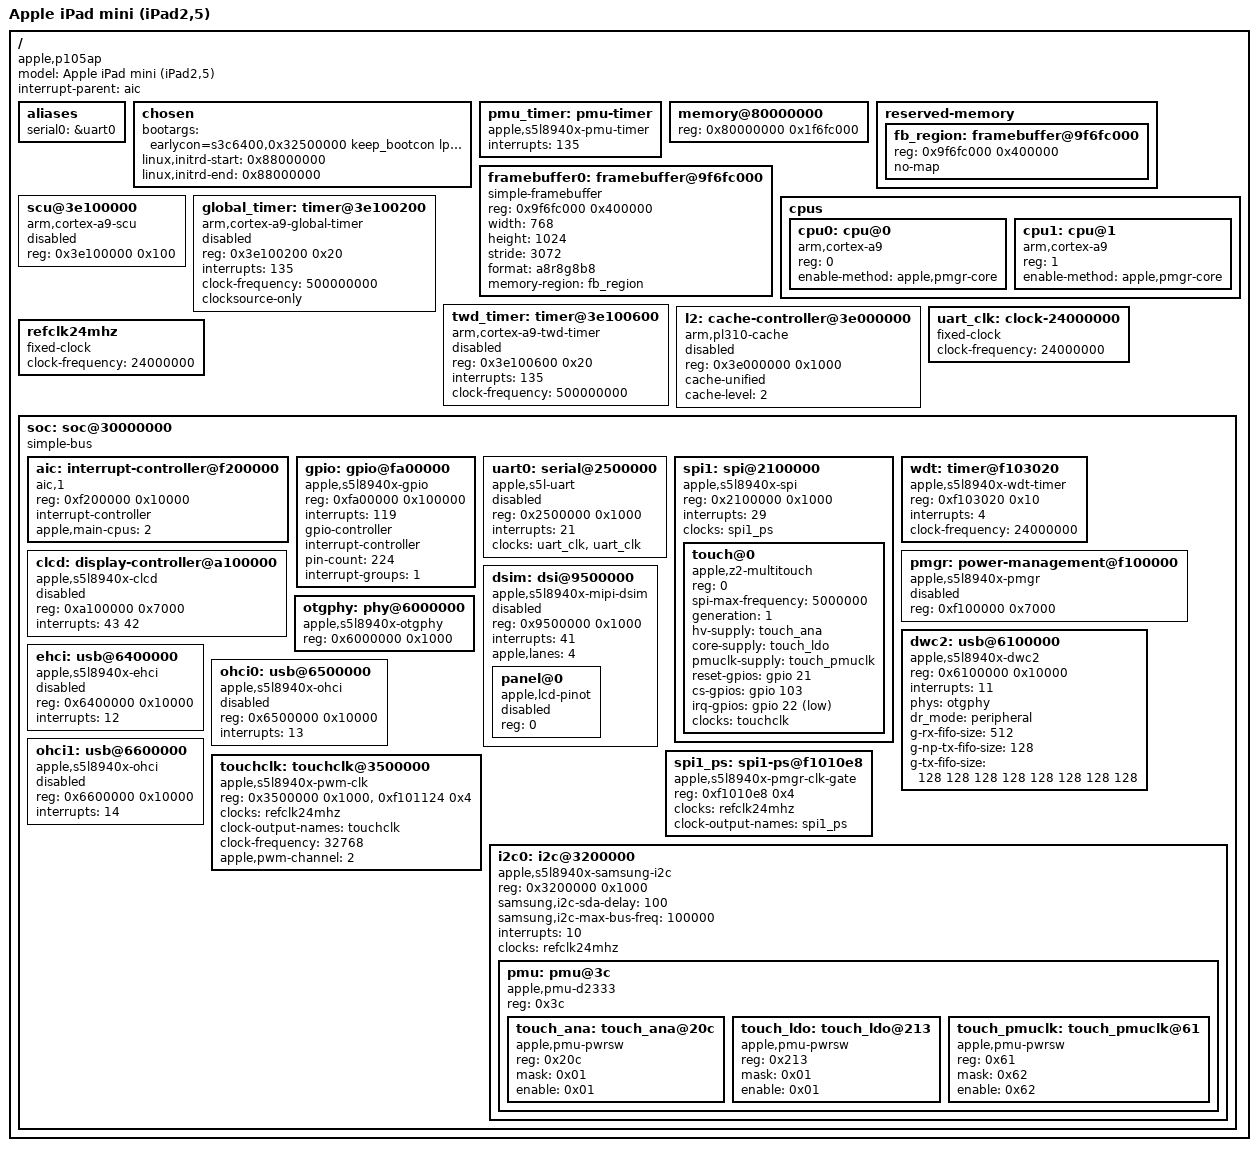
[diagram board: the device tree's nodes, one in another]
// SPDX-License-Identifier: GPL-2.0 OR MIT
/*
 * Apple iPad mini, 1st generation -- iPad2,5 / P105AP / S5L8942X (Apple A5).
 *
 * GENERATED FILE.  Do not edit by hand; edit scripts/gen_p105ap_dts.py and
 * re-run "make dts".  Every reg/interrupt below was read out of the iBoot
 * Apple Device Tree in src/adt-p105ap.bin, not transcribed from a datasheet.
 *
 * Scope: the minimum needed to bring Alpine + LXDE up on the glass, per
 * alpine-lxde-ramdisk-buildplan.md -- UART console, interrupt controller,
 * timer, simple-framebuffer, and an SPI transport for the touch controller.
 * NAND, GPU, ISP, audio, cameras and the sensor I2C buses are deliberately
 * absent; see DECISIONS.md.
 *
 * Address model
 * -------------
 * The ADT's "arm-io" node is a bus whose children use bus-local addresses:
 *   ranges = <0x0 0x30000000 0x10000000>
 * We keep that structure as /soc so unit addresses match the ADT one-for-one
 * and cross-checking against a fresh dump stays trivial.  usb-complex is a
 * second, nested bus; its children are flattened into /soc here because
 * nothing in Linux needs the extra level.
 *
 * Boot protocol (32-bit ARM):
 *   r0 = 0, r1 = ~0 (DT-only boot, no machine ID), r2 = <dtb physical address>
 */

/dts-v1/;

/ {
	compatible = "apple,p105ap", "apple,s5l8942x", "apple,s5l8940x", "apple,arm";
	model = "Apple iPad mini (iPad2,5)";
	#address-cells = <1>;
	#size-cells = <1>;
	interrupt-parent = <&aic>;

	aliases {
		serial0 = &uart0;
	};

	chosen {
		/*
		 * earlycon uses the Samsung s3c6400 driver: the S5L UART is a
		 * Samsung derivative with an identical register file (ULCON 0x00,
		 * UCON 0x04, UFCON 0x08, UTRSTAT 0x10, UTXH 0x20, URXH 0x24,
		 * UBRDIV 0x28).  See DECISIONS.md #3.
		 *
		 * No baud rate is given to earlycon on purpose: that tells it to
		 * keep whatever divisor iBoot already programmed, which avoids
		 * needing a clock rate we do not know.
		 *
		 * keep_bootcon matters here.  The full ttySAC0 port needs a clock
		 * provider; without keep_bootcon the kernel would drop earlycon
		 * if UART probe/baud fails.
		 *
		 * console=tty0 only.  Do NOT set stdout-path to serial0 — OF
		 * would still prefer ttySAC0 on probe (legacy console enabled)
		 * and /dev/console open fails for init.  UART still probes for
		 * /dev/ttySAC0; earlycon+keep_bootcon covers pre-fbcon printk.
		 */
		/*
		 * g_cdc.dev_addr / g_cdc.host_addr pin the two ends of the CDC
		 * ECM link.  Without them u_ether picks a fresh random MAC on
		 * every boot, and because macOS keys its interface names off the
		 * MAC, the gadget lands on a NEW enN each time -- en10, en11,
		 * en12 -- so the host-side ifconfig has to be redone every boot.
		 * Observed directly: 6e:f1:1c:27:f4:65 on one boot and
		 * da:5b:e0:9b:ef:1d on the next.
		 *
		 * Both are locally-administered unicast (low nibble of the first
		 * octet is 2), so they cannot collide with a real vendor OUI.
		 *   ...:01 = host side (the Mac's enN)
		 *   ...:02 = device side (usb0 here)
		 */
		bootargs = "earlycon=s3c6400,0x32500000 keep_bootcon lpj=5000000 root=/dev/ram0 rw rootwait panic=10 loglevel=8 ignore_loglevel g_cdc.host_addr=02:10:5a:05:00:01 g_cdc.dev_addr=02:10:5a:05:00:02";

		/*
		 * Placeholders.  The loader MUST overwrite both before jumping;
		 * scripts/fdt_fixup.py and the pongoOS module in pongo/ do this.
		 * Leaving them equal means "no initrd", which is a safe default.
		 */
		linux,initrd-start = <0x88000000>;
		linux,initrd-end   = <0x88000000>;
	};

	/*
	 * S5L894x maps DRAM at 0x80000000; iPad2,5 populates 512 MiB.
	 * The static ADT /memory node is zeroed (iBoot fills it at runtime),
	 * so this is a fixed constant rather than an extracted value.
	 */
	/*
	 * System tick from the Cortex-A9 PMU overflow interrupt.  No reg: the
	 * whole thing is CP15.
	 *
	 * hwirq 135 comes out of the ADT: cpu0 interrupts = <192, 135, 193> and
	 * cpu1 = <194, 139, 195>, with function-ipi_dispatch pointing at 192 and
	 * ipi_dispatch_other at 193 -- so the outer two are IPIs and the middle
	 * one is the per-CPU interrupt.  aic target-destinations = <135 cpu0,
	 * 139 cpu1> pins each to its own core.  On an A9 with no architected
	 * timer, that per-CPU line is nPMUIRQ.
	 */
	pmu_timer: pmu-timer {
		compatible = "apple,s5l8940x-pmu-timer";
		interrupts = <135>;
		status = "okay";
	};

	memory@80000000 {
		device_type = "memory";
		reg = <0x80000000 0x1f6fc000>;
	};

	reserved-memory {
		#address-cells = <1>;
		#size-cells = <1>;
		ranges;

		/*
		 * iBoot's scanout buffer.  Must be no-map so the kernel never
		 * hands these pages to the allocator while the CLCD is still
		 * DMA-ing out of them.  Base is patched at boot together with
		 * the framebuffer node below.
		 */
		fb_region: framebuffer@9f6fc000 {
			reg = <0x9f6fc000 0x400000>;
			no-map;
		};
	};

	/*
	 * simple-framebuffer over iBoot's already-running CLCD scanout.
	 *
	 * The static ADT's /vram node has reg = <0 0>: the base is assigned by
	 * iBoot at runtime.  The loader reads the LIVE ADT's /vram (pongoOS
	 * keeps iBoot's device tree in memory) and patches reg[0] here plus
	 * fb_region above.  Portrait Recovery scanout: 768x1024, stride 3072.
	 *
	 * TODO: confirm the pixel order on hardware.  a8r8g8b8 is what iBoot
	 * uses on every other A5-era device, but if the display comes up with
	 * red and blue swapped, change this to "x8b8g8r8" -- it is the only
	 * value here that cannot be checked without looking at the panel.
	 */
	framebuffer0: framebuffer@9f6fc000 {
		compatible = "simple-framebuffer";
		reg = <0x9f6fc000 0x400000>;
		width = <768>;
		height = <1024>;
		stride = <3072>;
		format = "a8r8g8b8";
		memory-region = <&fb_region>;
		status = "okay";
	};

	cpus {
		#address-cells = <1>;
		#size-cells = <0>;

		cpu0: cpu@0 {
			device_type = "cpu";
			compatible = "arm,cortex-a9";
			reg = <0>;
			enable-method = "apple,pmgr-core";
		};

		/*
		 * Dual-core A5: cpu1 brought up via PMGR function-enable_core
		 * ("Core", arg 2) + AIC IPI_SEND.  See docs/p105-smp-bringup.md.
		 */
		cpu1: cpu@1 {
			device_type = "cpu";
			compatible = "arm,cortex-a9";
			reg = <1>;
			enable-method = "apple,pmgr-core";
		};
	};

	/*
	 * Cortex-A9 private memory region (SCU + global timer + private timers).
	 *
	 * PERIPHBASE is NOT in the ADT.  The candidate below is the second reg
	 * entry of the ADT "pl310" node -- 0x2000 long, which is exactly the
	 * size of the A9 private memory map, so it is almost certainly right.
	 * It is still a guess, so every consumer is disabled by default.
	 *
	 * Do not trust this file for it: Cortex-A9 exposes PERIPHBASE in the
	 * CBAR register (mrc p15, 4, rX, c15, c0, 0).  docs/read-cbar.md shows
	 * how to print it from a pongoOS shell; once confirmed, flip the three
	 * nodes below to "okay" (or let the loader do it).
	 *
	 * The interrupt numbers are equally provisional: 135 is the middle
	 * cell of the ADT cpu0 "interrupts" tuple <0xc0 0x87 0xc1>, which by Apple
	 * convention is <ipi-self, timer, ipi-other>.  That the A9 private timer
	 * output is what reaches the AIC on that line is an inference, not a fact.
	 */
	scu@3e100000 {
		compatible = "arm,cortex-a9-scu";
		reg = <0x3e100000 0x100>;
		status = "disabled";
	};

	global_timer: timer@3e100200 {
		compatible = "arm,cortex-a9-global-timer";
		reg = <0x3e100200 0x20>;
		interrupts = <135>;
		clock-frequency = <500000000>;
		/* Counter + udelay only. Comparator IRQ is not routed like a GIC PPI. */
		clocksource-only;
		status = "disabled";
	};

	twd_timer: timer@3e100600 {
		compatible = "arm,cortex-a9-twd-timer";
		reg = <0x3e100600 0x20>;
		interrupts = <135>;
		clock-frequency = <500000000>;
		status = "disabled";
	};

	l2: cache-controller@3e000000 {
		compatible = "arm,pl310-cache";
		reg = <0x3e000000 0x1000>;
		cache-unified;
		cache-level = <2>;
		/*
		 * iBoot already enabled PL310. Driving it from Linux with
		 * SCTLR.C=0 hangs in outer_cache / slab (stuck at mm_slab).
		 * Leave the hardware on; do not register outer_cache ops.
		 */
		status = "disabled";
	};

	/*
	 * Placeholder UART clock for samsung_tty probe (no PMGR yet).
	 * Rate is invented; glass console uses tty0 and does not need it.
	 */
	uart_clk: clock-24000000 {
		compatible = "fixed-clock";
		#clock-cells = <0>;
		clock-frequency = <24000000>;
	};

	/* 24 MHz reference for the touch-clock (Cmwp) block. */
	refclk24mhz: refclk24mhz {
		compatible = "fixed-clock";
		#clock-cells = <0>;
		clock-frequency = <24000000>;
	};

	soc: soc@30000000 {
		compatible = "simple-bus";
		#address-cells = <1>;
		#size-cells = <1>;
		ranges = <0x0 0x30000000 0x10000000>;

		/*
		 * Apple Interrupt Controller revision 1 ("aic,1"), per ADT.
		 *
		 * Custom driver: drivers/irqchip/irq-apple-aic1.c
		 * Not compatible with arm64 drivers/irqchip/irq-apple-aic.c.
		 *
		 * #interrupt-cells = 1: bare hardware IRQ index (no type/flags).
		 */
		aic: interrupt-controller@f200000 {
			compatible = "aic,1";
			reg = <0xf200000 0x10000>;
			interrupt-controller;
			#interrupt-cells = <1>;
			#address-cells = <0>;	/* dtc wants it on every interrupt provider */
			apple,main-cpus = <2>;
		};

		/*
		 * GPIO block.  28 ports, 8 interrupt groups
		 * multiplexed onto a single AIC line.  Needed here only because
		 * the touch controller's attention line hangs off it.
		 *
		 * TODO: no upstream driver binds apple,s5l8940x-gpio.  Until one
		 * exists the touchscreen child below cannot get a real interrupt
		 * and the userspace daemon must poll.  Kept in the DT so the
		 * wiring is recorded.
		 */
		gpio: gpio@fa00000 {
            compatible = "apple,s5l8940x-gpio";
            reg = <0xfa00000 0x100000>;
            interrupts = <119>;
            gpio-controller;
            #gpio-cells = <2>;
            interrupt-controller;
            #interrupt-cells = <2>;
            #address-cells = <0>;
            pin-count = <224>;
            interrupt-groups = <1>;
            status = "okay";
        };

		/*
		 * Boot console.  The ADT marks this node "boot-console" and gives
		 * it a "debug-console" child, so iBoot has already configured the
		 * pin muxing, the clock gate and 115200 8N1 -- we only have to
		 * keep using it.  compatible lists the Samsung part second so the
		 * stock samsung_tty driver binds even without our patch.
		 *
		 * clocks: samsung_tty requires clk_get("uart") + baud clk.
		 * PMGR is unmodelled; a fixed 24 MHz placeholder lets the port
		 * probe.  Baud may be wrong for USB-TTL until the real rate is
		 * known — on-glass console=tty0 does not depend on it.
		 */
		uart0: serial@2500000 {
			compatible = "apple,s5l-uart", "samsung,s3c6400-uart";
			reg = <0x2500000 0x1000>;
			interrupts = <21>;
			clocks = <&uart_clk>, <&uart_clk>;
			clock-names = "uart", "clk_uart_baud0";
			status = "disabled";
		};

		/*
		 * SPI1 -- transport for the multi-touch controller.
		 *
		 * Exposed as spidev on purpose.  Per the build plan, v1 drives the
		 * panel from a userspace daemon that speaks Apple's Z2 protocol
		 * and injects events via uinput; writing a kernel multitouch
		 * driver is explicitly out of scope for "LXDE on glass".
		 *
		 * Bound by the Sandcastle-port spi-s5l8940x.c (built from
		 * patches/files-sandcastle-port/).  The ADT records DMA channels
		 * 11/12 on the cdma controller if PIO ever becomes the bottleneck.
		 */
				spi1: spi@2100000 {
			compatible = "apple,s5l8940x-spi";
			reg = <0x2100000 0x1000>;
			interrupts = <29>;
			clocks = <&spi1_ps>;
			#address-cells = <1>;
			#size-cells = <0>;
			status = "okay";

			touch@0 {
				compatible = "apple,z2-multitouch";
				reg = <0>;
				spi-max-frequency = <5000000>;
				generation = <1>;
				hv-supply = <&touch_ana>;
				core-supply = <&touch_ldo>;
				pmuclk-supply = <&touch_pmuclk>;
				/* The ADT writes GPIOs as (port << 8) | pin, eight
				 * to a port: function-reset 0x0205 is pin 21,
				 * function-enable_cs 0x0c07 is pin 103.  The ATTN
				 * interrupt is already a plain number, 22. */
				reset-gpios = <&gpio 21 0>;
				cs-gpios = <&gpio 103 0>;
				irq-gpios = <&gpio 22 1>;
				clocks = <&touchclk>;
			};
		};

		/*
		 * Watchdog block -- used here as the system TICK, not as a watchdog.
		 *
		 * ADT /arm-io/wdt: reg = 0x0F103020 size 0x10, interrupts = <4>,
		 * clock-ids = <4>.  It is a sub-window of PMGR, whose ADT
		 * device_type is literally "timer".  A userspace scan of the whole
		 * PMGR window found exactly one free-running word in it, at +0x00
		 * of this node (phys 0x3F103020) -- CUR_TIME.  BITE/BARK/CTRL
		 * beside it read 0: iBoot leaves the dog disarmed.
		 *
		 * Layout matches what mainline documents for the same IP family in
		 * drivers/watchdog/apple_wdt.c:
		 *   +0x00 CUR_TIME  +0x04 BITE_TIME  +0x08 BARK_TIME  +0x0c CTRL
		 *
		 * Only the BARK (interrupt) half is used.  CTRL.RESET_EN would
		 * reset the device mid-debug and is never written -- so this is
		 * safe to leave enabled, unlike a real watchdog nobody pets.
		 *
		 * clock-frequency is the 24 MHz SoC reference.  If the tick runs
		 * fast or slow, measure CUR_TIME over a wall-clock minute and put
		 * the real number here; nothing else needs changing.
		 */
		wdt: timer@f103020 {
			compatible = "apple,s5l8940x-wdt-timer";
			reg = <0xf103020 0x10>;
			interrupts = <4>;
			clock-frequency = <24000000>;
			/* CTRL implemented-bit mask is 0x0d (write 0xff, read 0x0d):
			 * BIT(0) IRQ_EN, BIT(1) write-1-clear IRQ_STATUS, BIT(2)
			 * RESET_EN (never set), BIT(3) v1-only and undocumented.
			 * Which compare is the bark, and whether BIT(3) is needed,
			 * are swept by the driver at late_initcall -- see
			 * arch/arm/mach-apple/apple_wdt_clkevt.c. */
			status = "okay";
		};

		/*
		 * Power/clock manager.  Modelled only so the address space is
		 * documented -- we rely entirely on iBoot having left every clock
		 * we use already ungated.  Enabling this without a driver that
		 * understands the ADT device-clocks table would gate the UART.
		 */
		pmgr: power-management@f100000 {
			compatible = "apple,s5l8940x-pmgr", "syscon";
			reg = <0xf100000 0x7000>;
			status = "disabled";
		};

		/*
		 * Display pipeline, recorded but unused.  simplefb above reuses
		 * the output of these blocks rather than reprogramming them; a
		 * real CLCD + MIPI-DSI driver for S5L8940X does not exist and is
		 * not needed to get a desktop on screen.
		 */
		clcd: display-controller@a100000 {
			compatible = "apple,s5l8940x-clcd";
			reg = <0xa100000 0x7000>;
			interrupts = <43 42>;
			status = "disabled";
		};

		dsim: dsi@9500000 {
			compatible = "apple,s5l8940x-mipi-dsim", "samsung,mipi-dsim-1";
			reg = <0x9500000 0x1000>;
			interrupts = <41>;
			#address-cells = <1>;
			#size-cells = <0>;
			apple,lanes = <4>;
			status = "disabled";

			panel@0 {
				compatible = "apple,lcd-pinot";
				reg = <0>;
				status = "disabled";
			};
		};

		/*
		 * USB.  Kept because the BCM4334 Wi-Fi part is USB-attached on
		 * this board (ADT puts /wlan under usb-complex/usb-ehci, not
		 * SDIO), so brcmfmac later needs a working EHCI.  Off for now:
		 * the OTG PHY needs bringing up first and it is not on the
		 * critical path to a desktop.
		 *
		 * Addresses are flattened through the usb-complex bus, whose own
		 * ranges map child 0 to 0x6100000 within arm-io; EHCI's ADT reg of
		 * 0x300000 therefore lands at 0x6400000 here, 0x36400000 physical.
		 */
		otgphy: phy@6000000 {
			compatible = "apple,s5l8940x-otgphy";
			reg = <0x6000000 0x1000>;
			#phy-cells = <0>;
			status = "okay";
		};

		/* DWC2 USB-OTG device controller.
		 * ADT: usb-device @ usb-complex+0 = phys 0x36100000, IRQ 11,
		 * num-of-eps=14, fifo-depth=0x820.
		 * PMGR gates from usb-complex: 87, 88, 89, 90, 91 (5 gates)
		 * plus main clock ID 292. */
		dwc2: usb@6100000 {
			compatible = "apple,s5l8940x-dwc2", "snps,dwc2";
			reg = <0x6100000 0x10000>;
			interrupts = <11>;
			phys = <&otgphy>;
			phy-names = "usb2-phy";
			dr_mode = "peripheral";
			g-rx-fifo-size = <512>;
			g-np-tx-fifo-size = <128>;
			g-tx-fifo-size = <128 128 128 128 128 128 128 128>;
			status = "okay";
		};

		ehci: usb@6400000 {
			compatible = "apple,s5l8940x-ehci", "generic-ehci";
			reg = <0x6400000 0x10000>;
			interrupts = <12>;
			status = "disabled";
		};

		ohci0: usb@6500000 {
			compatible = "apple,s5l8940x-ohci", "generic-ohci";
			reg = <0x6500000 0x10000>;
			interrupts = <13>;
			status = "disabled";
		};

		ohci1: usb@6600000 {
			compatible = "apple,s5l8940x-ohci", "generic-ohci";
			reg = <0x6600000 0x10000>;
			interrupts = <14>;
			status = "disabled";
		};
        /*
         * ---- Sandcastle-port additions (touch stack) ----
         *
         * touchclk is the digitizer's 32 kHz clock, and on A5 it is PWM
         * channel 2 (ADT /arm-io/pwm, child grape-clk, reg = 2): 366 + 366
         * ticks of the 24 MHz reference, out on GPIO 63.  reg[1] is the PWM
         * block's power-state register -- index 73 of the ADT's
         * device-clocks table, not the clock-gates id 83.
         * docs/research/p105-pwm-block.md, p105-pmgr-gates.md.
         */
        touchclk: touchclk@3500000 {
            compatible = "apple,s5l8940x-pwm-clk";
            #clock-cells = <0>;
            reg = <0x3500000 0x1000>, <0xf101124 0x4>;
            clocks = <&refclk24mhz>;
            clock-output-names = "touchclk";
            clock-frequency = <32768>;
            apple,pwm-channel = <2>;
        };

        /* SPI1's power-state switch: device-clocks index 58, clock-gates id
         * 68.  The SPI driver enables it as its clock. */
        spi1_ps: spi1-ps@f1010e8 {
            compatible = "apple,s5l8940x-pmgr-clk-gate";
            #clock-cells = <0>;
            reg = <0xf1010e8 0x4>;
            clocks = <&refclk24mhz>;
            clock-output-names = "spi1_ps";
        };

        i2c0: i2c@3200000 {
            compatible = "apple,s5l8940x-samsung-i2c";
            reg = <0x3200000 0x1000>;
            samsung,i2c-sda-delay = <100>;
            samsung,i2c-max-bus-freq = <100000>;
            interrupts = <10>;
            clocks = <&refclk24mhz>;
            clock-names = "i2c";
            pinctrl-names = "default";
            /* no pinctrl-0 - just an empty default state so samsung driver
             * skips gpio path (pins 4,5 already forced to iic by pinctrl driver) */
            #address-cells = <1>;
            #size-cells = <0>;
            status = "okay";

            pmu: pmu@3c {
                compatible = "apple,pmu-d2333";
                reg = <0x3c>;
                #address-cells = <1>;
                #size-cells = <0>;

                touch_ana: touch_ana@20c {
                    compatible = "apple,pmu-pwrsw";
                    reg = <0x20c>;
                    mask = <0x01>;
                    enable = <0x01>;
                };

                touch_ldo: touch_ldo@213 {
                    compatible = "apple,pmu-pwrsw";
                    reg = <0x213>;
                    mask = <0x01>;
                    enable = <0x01>;
                };

                /* ADT function-clock_enable-pmu: PMU GPIO0.  The register is
                 * gpio + 0x61 (AppleD1946PMU::_setGPIOFunction in the 12H321
                 * kernelcache), so GPIO0 is 0x61 -- not 0x200, which is the
                 * LDO range.  0x60 is the direction/enable field and 0x02 the
                 * output level; 0x1d is preserved config.  We drive it as an
                 * enabled output: if the level turns out to be inverted this
                 * is one hex digit (enable = <0x60>). */
                touch_pmuclk: touch_pmuclk@61 {
                    compatible = "apple,pmu-pwrsw";
                    reg = <0x61>;
                    mask = <0x62>;
                    enable = <0x62>;
                };
            };
        };

	};
};
